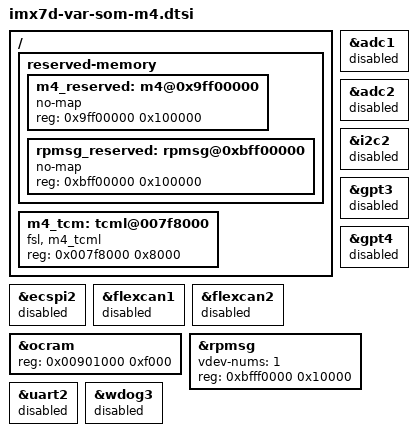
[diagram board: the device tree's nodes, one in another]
// SPDX-License-Identifier: GPL-2.0+ OR MIT
//
// Copyright (C) 2016-2022 Variscite Ltd.

/ {
	reserved-memory {
		#address-cells = <1>;
		#size-cells = <1>;
		ranges;

		m4_reserved: m4@0x9ff00000 {
			no-map;
			reg = <0x9ff00000 0x100000>;
		};

		rpmsg_reserved: rpmsg@0xbff00000 {
			no-map;
			reg = <0xbff00000 0x100000>;
		};
	};
	m4_tcm: tcml@007f8000 {
		compatible = "fsl, m4_tcml";
		reg = <0x007f8000 0x8000>;
	};
};

&adc1 {
	status = "disabled";
};

&adc2 {
	status = "disabled";
};

&ecspi2 {
	status = "disabled";
};

&flexcan1 {
	status = "disabled";
};

&flexcan2 {
	status = "disabled";
};

&i2c2 {
	status = "disabled";
};

&gpt3 {
	status = "disabled";
};

&gpt4 {
	status = "disabled";
};

&ocram {
	reg = <0x00901000 0xf000>;
};

&rpmsg{
	vdev-nums = <1>;
	reg = <0xbfff0000 0x10000>;
	status = "okay";
};

&uart2 {
	status = "disabled";
};

&wdog3{
	status = "disabled";
};
